# HSM_TC3xx register map
Vendor: Infineon; Series: AURIX TC3xx; File version: 2.0
CPU: CM3 r2p0, little endian, MPU, no FPU, 3 interrupt priority bits
Registers are 32-bit, read-write, no defined reset value unless marked. A register's access mark holds for its fields unless they carry their own. Offsets are from the block's base; [hi:lo] are bit positions; {n}, {i} and the like mark numbered series.

## HSM_COREDEBUG — Cortex-M3 core debug registers. Used by the debug server for run control; read-only here.
Base 0xE000EDF0
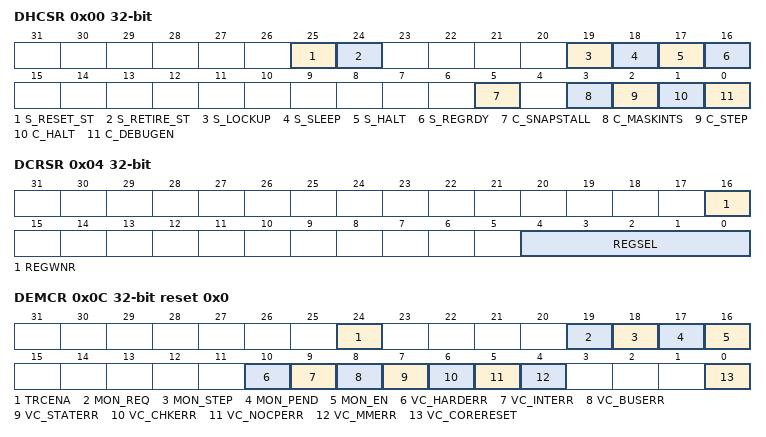
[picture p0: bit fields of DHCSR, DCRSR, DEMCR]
0x00 DHCSR ro — Debug Halting Control and Status Register (reading clears S_RESET_ST and S_RETIRE_ST)
  [25] S_RESET_ST — Core reset since last read
  [24] S_RETIRE_ST — Instruction retired since last read
  [19] S_LOCKUP — Core locked up
  [18] S_SLEEP — Core sleeping
  [17] S_HALT — Core halted
  [16] S_REGRDY — Register transfer complete
  [5] C_SNAPSTALL — Break a stalled load/store
  [3] C_MASKINTS — Mask interrupts while stepping
  [2] C_STEP — Step
  [1] C_HALT — Halt
  [0] C_DEBUGEN — Halting debug enabled (HSM SW may only set it when HSM debugging is enabled)
0x04 DCRSR wo — Debug Core Register Selector Register
  [16] REGWNR — 1: write, 0: read
  [4:0] REGSEL — Core register
0x08 DCRDR ro — Debug Core Register Data Register
  [31:0] DBGTMP — Core register transfer data
0x0C DEMCR ro reset 0x0 — Debug Exception and Monitor Control Register
  [24] TRCENA — DWT enable
  [19] MON_REQ — Monitor request
  [18] MON_STEP — Monitor step
  [17] MON_PEND — Monitor pending
  [16] MON_EN — Debug monitor enable
  [10] VC_HARDERR — Vector catch HardFault
  [9] VC_INTERR — Vector catch exception entry/return fault
  [8] VC_BUSERR — Vector catch BusFault
  [7] VC_STATERR — Vector catch UsageFault state error
  [6] VC_CHKERR — Vector catch UsageFault check error
  [5] VC_NOCPERR — Vector catch UsageFault coprocessor
  [4] VC_MMERR — Vector catch MemManage
  [0] VC_CORERESET — Vector catch core reset

## HSM_DWT — Cortex-M3 data watchpoint and trace unit, 4 comparators. The comparators are used by the debug server for watchpoints; read-only here.
Base 0xE0001000
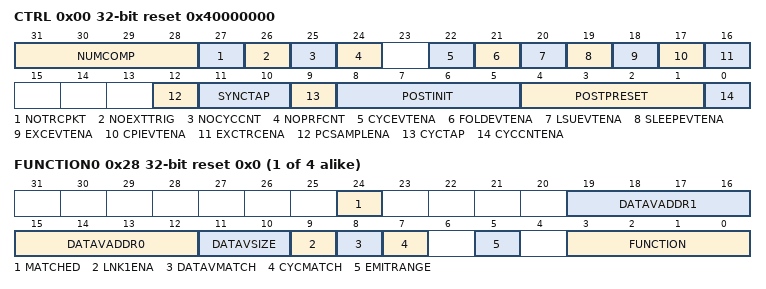
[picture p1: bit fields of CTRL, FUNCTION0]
0x00 CTRL reset 0x40000000 (reset mask 0xF0000000) — DWT Control Register
  [31:28] NUMCOMP ro — Number of comparators
  [27] NOTRCPKT ro — No trace packets
  [26] NOEXTTRIG ro — No external match signals
  [25] NOCYCCNT ro — No cycle counter
  [24] NOPRFCNT ro — No profiling counters
  [22] CYCEVTENA — POSTCNT underflow event
  [21] FOLDEVTENA — Folded instruction count event
  [20] LSUEVTENA — LSU count event
  [19] SLEEPEVTENA — Sleep count event
  [18] EXCEVTENA — Exception overhead count event
  [17] CPIEVTENA — CPI count event
  [16] EXCTRCENA — Exception trace
  [12] PCSAMPLENA — PC sampling
  [11:10] SYNCTAP — Synchronization packet rate
  [9] CYCTAP — POSTCNT tap
  [8:5] POSTINIT — POSTCNT initial value
  [4:1] POSTPRESET — POSTCNT reload value
  [0] CYCCNTENA — Cycle counter enable
0x04 CYCCNT — Cycle Count Register
  [31:0] CYCCNT — Processor clock cycles
0x08 CPICNT — CPI Count Register
  [7:0] CPICNT — Additional instruction cycles
0x0C EXCCNT — Exception Overhead Count Register
  [7:0] EXCCNT — Exception overhead cycles
0x10 SLEEPCNT — Sleep Count Register
  [7:0] SLEEPCNT — Sleep cycles
0x14 LSUCNT — LSU Count Register
  [7:0] LSUCNT — Load/store extra cycles
0x18 FOLDCNT — Folded-instruction Count Register
  [7:0] FOLDCNT — Folded instructions
0x1C PCSR ro — Program Counter Sample Register
  [31:0] EIASAMPLE — Sampled instruction address
{0x20+0x10*i} COMP{i} ro (i=0..3) — Comparator Register {i}
  [31:0] COMP — Reference value
{0x24+0x10*i} MASK{i} ro (i=0..3) — Mask Register {i}
  [4:0] MASK — Ignored address bits
{0x28+0x10*i} FUNCTION{i} ro reset 0x0 (i=0..3) — Function Register {i} (reading clears MATCHED)
  [24] MATCHED — Comparator matched since last read
  [19:16] DATAVADDR1 — Second linked comparator
  [15:12] DATAVADDR0 — Linked address comparator
  [11:10] DATAVSIZE — Data value size
  [9] LNK1ENA — Second linked comparator supported
  [8] DATAVMATCH — Data value match
  [7] CYCMATCH — Cycle count match
  [5] EMITRANGE — Emit address offset trace packets
  [3:0] FUNCTION — Function (4: PC, 5: read, 6: write, 7: access watchpoint)

## HSM_FPB — Cortex-M3 flash patch and breakpoint unit, 6 usable code comparators with the HSM's FP_COMPHx extension for 32-bit addresses (HSM TS 12.4.1). Used by the debug server for breakpoints; read-only here.
Base 0xE0002000
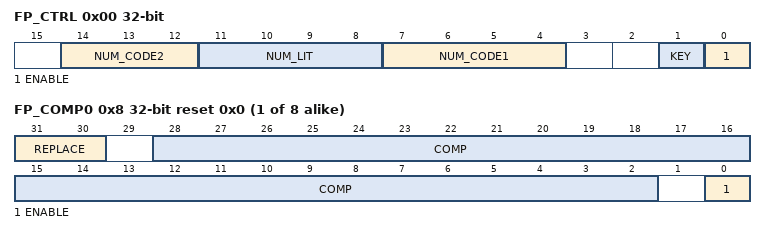
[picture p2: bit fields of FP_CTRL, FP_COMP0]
0x00 FP_CTRL ro — Flash Patch Control Register
  [14:12] NUM_CODE2 — Code comparators, bits 6:4
  [11:8] NUM_LIT — Literal comparators
  [7:4] NUM_CODE1 — Code comparators, bits 3:0
  [1] KEY — Write key (must be 1 on writes). Reads as 0.
  [0] ENABLE — FPB enable
0x04 FP_REMAP ro — Flash Patch Remap Register
  [28:5] REMAP — Remap base address
{0x8+4i} FP_COMP{i} ro reset 0x0 (i=0..7) — Flash Patch Comparator Register {i} (6 and 7 are literal comparators, unused on the HSM)
  [31:30] REPLACE — Breakpoint on lower/upper halfword or both
  [28:2] COMP — Comparison address bits 28:2
  [0] ENABLE — Comparator enable
{0x28+4i} FP_COMPH{i} ro reset 0x0 (i=0..7) — Flash Patch Comparator High Register {i} (HSM extension)
  [2:0] COMPH — Comparison address bits 31:29
0xFD0 PID4 ro reset 0x0 — Peripheral Identification Register 4
  [31:0] PID — PID value
0xFE0 PID0 ro reset 0x1 — Peripheral Identification Register 0
  [31:0] PID — PID value
0xFE4 PID1 ro reset 0x10 — Peripheral Identification Register 1
  [31:0] PID — PID value
0xFE8 PID2 ro reset 0x1C — Peripheral Identification Register 2
  [31:0] PID — PID value
0xFEC PID3 ro reset 0x1 — Peripheral Identification Register 3
  [31:0] PID — PID value
{0xFF0+4i} CID{i} ro (i=0..3) — Component Identification Register {i}
  [7:0] CID — Component ID byte
